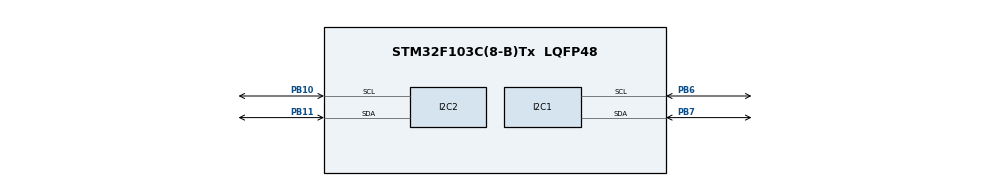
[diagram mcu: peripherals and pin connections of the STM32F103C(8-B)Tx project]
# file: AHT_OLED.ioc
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Mcu.Family=STM32F1
Mcu.Name=STM32F103C(8-B)Tx
Mcu.Package=LQFP48
NVIC.PriorityGroup=NVIC_PRIORITYGROUP_4
PA13.Mode=Serial_Wire
PA13.Signal=SYS_JTMS-SWDIO
PA14.Mode=Serial_Wire
PA14.Signal=SYS_JTCK-SWCLK
PB10.Mode=I2C
PB10.Signal=I2C2_SCL
PB11.Mode=I2C
PB11.Signal=I2C2_SDA
PB6.Mode=I2C
PB6.Signal=I2C1_SCL
PB7.Mode=I2C
PB7.Signal=I2C1_SDA
PD0-OSC_IN.Mode=HSE-External-Oscillator
PD0-OSC_IN.Signal=RCC_OSC_IN
PD1-OSC_OUT.Mode=HSE-External-Oscillator
PD1-OSC_OUT.Signal=RCC_OSC_OUT
ProjectManager.HeapSize=0x200
ProjectManager.StackSize=0x400
ProjectManager.TargetToolchain=MDK-ARM V5.32
RCC.APB1Freq_Value=8000000
RCC.APB2Freq_Value=8000000
board=custom

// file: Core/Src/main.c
/* USER CODE BEGIN Header */
/**
  ******************************************************************************
  * @file           : main.c
  * @brief          : Main program body
  ******************************************************************************
  * @attention
  *
  * Copyright (c) 2023 STMicroelectronics.
  * All rights reserved.
  *
  * This software is licensed under terms that can be found in the LICENSE file
  * in the root directory of this software component.
  * If no LICENSE file comes with this software, it is provided AS-IS.
  *
  ******************************************************************************
  */
/* USER CODE END Header */
#include "main.h"
#include "i2c.h"
#include "gpio.h"

/* USER CODE BEGIN Includes */
#include "oled.h"
#include "AHT20.h"
#include "stdio.h"
/* USER CODE END Includes */

/* USER CODE BEGIN PD */
char temp_buffer[100];
char RH_buffer[100];
/* USER CODE END PD */

void SystemClock_Config(void);

int main(void)
{

  /* MCU Configuration--------------------------------------------------------*/

  /* Reset of all peripherals, Initializes the Flash interface and the Systick. */
  HAL_Init();

  /* Configure the system clock */
  SystemClock_Config();

  /* Initialize all configured peripherals */
  MX_GPIO_Init();
  MX_I2C1_Init();
  MX_I2C2_Init();
  OLED_Init();
  OLED_Clear();
int flag=AHT20_Init();

  /* Infinite loop */
  while (1)
  {
    if (flag==0){
      Humiture.alive=1;
     AHT20_Get_Value(&Humiture);
      OLED_ShowCHinese(0,0,0);//温
      OLED_ShowCHinese(18,0,2);//度
      OLED_ShowCHinese(0,2,1);//湿
      OLED_ShowCHinese(18,2,2);//度
      sprintf(temp_buffer,":%.2f",Humiture.Temp);
      OLED_ShowString(36,0,(uint8_t*)temp_buffer,16);
     sprintf(RH_buffer,":%.2f",Humiture.RH);
OLED_ShowString(36,2,RH_buffer,16);
    }
    else{
      OLED_Clear();
      Humiture.alive=0;
  OLED_ShowCHinese(0,0,0);
  OLED_ShowCHinese(18,0,1);
  OLED_ShowCHinese(36,0,2);
  OLED_ShowCHinese(54,0,3);
  OLED_ShowCHinese(72,0,4);
  OLED_ShowCHinese(90,0,5);
  OLED_ShowCHinese(108,0,6);
    }
    HAL_Delay(2000);

  }
}

void SystemClock_Config(void)
{
  RCC_OscInitTypeDef RCC_OscInitStruct = {0};
  RCC_ClkInitTypeDef RCC_ClkInitStruct = {0};

  /** Initializes the RCC Oscillators according to the specified parameters
  * in the RCC_OscInitTypeDef structure.
  */
  RCC_OscInitStruct.OscillatorType = RCC_OSCILLATORTYPE_HSI;
  RCC_OscInitStruct.HSIState = RCC_HSI_ON;
  RCC_OscInitStruct.HSICalibrationValue = RCC_HSICALIBRATION_DEFAULT;
  RCC_OscInitStruct.PLL.PLLState = RCC_PLL_NONE;
  if (HAL_RCC_OscConfig(&RCC_OscInitStruct) != HAL_OK)
  {
    Error_Handler();
  }

  /** Initializes the CPU, AHB and APB buses clocks
  */
  RCC_ClkInitStruct.ClockType = RCC_CLOCKTYPE_HCLK|RCC_CLOCKTYPE_SYSCLK
                              |RCC_CLOCKTYPE_PCLK1|RCC_CLOCKTYPE_PCLK2;
  RCC_ClkInitStruct.SYSCLKSource = RCC_SYSCLKSOURCE_HSI;
  RCC_ClkInitStruct.AHBCLKDivider = RCC_SYSCLK_DIV1;
  RCC_ClkInitStruct.APB1CLKDivider = RCC_HCLK_DIV1;
  RCC_ClkInitStruct.APB2CLKDivider = RCC_HCLK_DIV1;

  if (HAL_RCC_ClockConfig(&RCC_ClkInitStruct, FLASH_LATENCY_0) != HAL_OK)
  {
    Error_Handler();
  }
}

void Error_Handler(void)
{
  __disable_irq();
  while (1)
  {
  }
}
